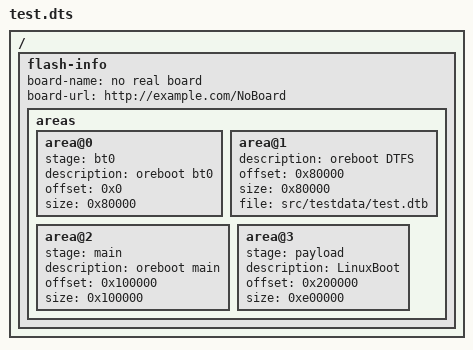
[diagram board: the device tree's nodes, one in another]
/dts-v1/;

/ {
    #address-cells = <1>;
    #size-cells = <1>;

    flash-info {
        board-name = "no real board";
        board-url = "http://example.com/NoBoard";
        areas {
            area@0 {
                stage = "bt0";
                description = "oreboot bt0";
                offset = <0x0>;
                size = <0x80000>;
            };
            area@1 {
                description = "oreboot DTFS";
                offset = <0x80000>;
                size = <0x80000>;
                file = "src/testdata/test.dtb";
            };
            area@2 {
                stage = "main";
                description = "oreboot main";
                offset = <0x100000>;
                size = <0x100000>;
            };
            area@3 {
                stage = "payload";
                description = "LinuxBoot";
                offset = <0x200000>;
                size = <0xe00000>;
            };
        };
    };
};
